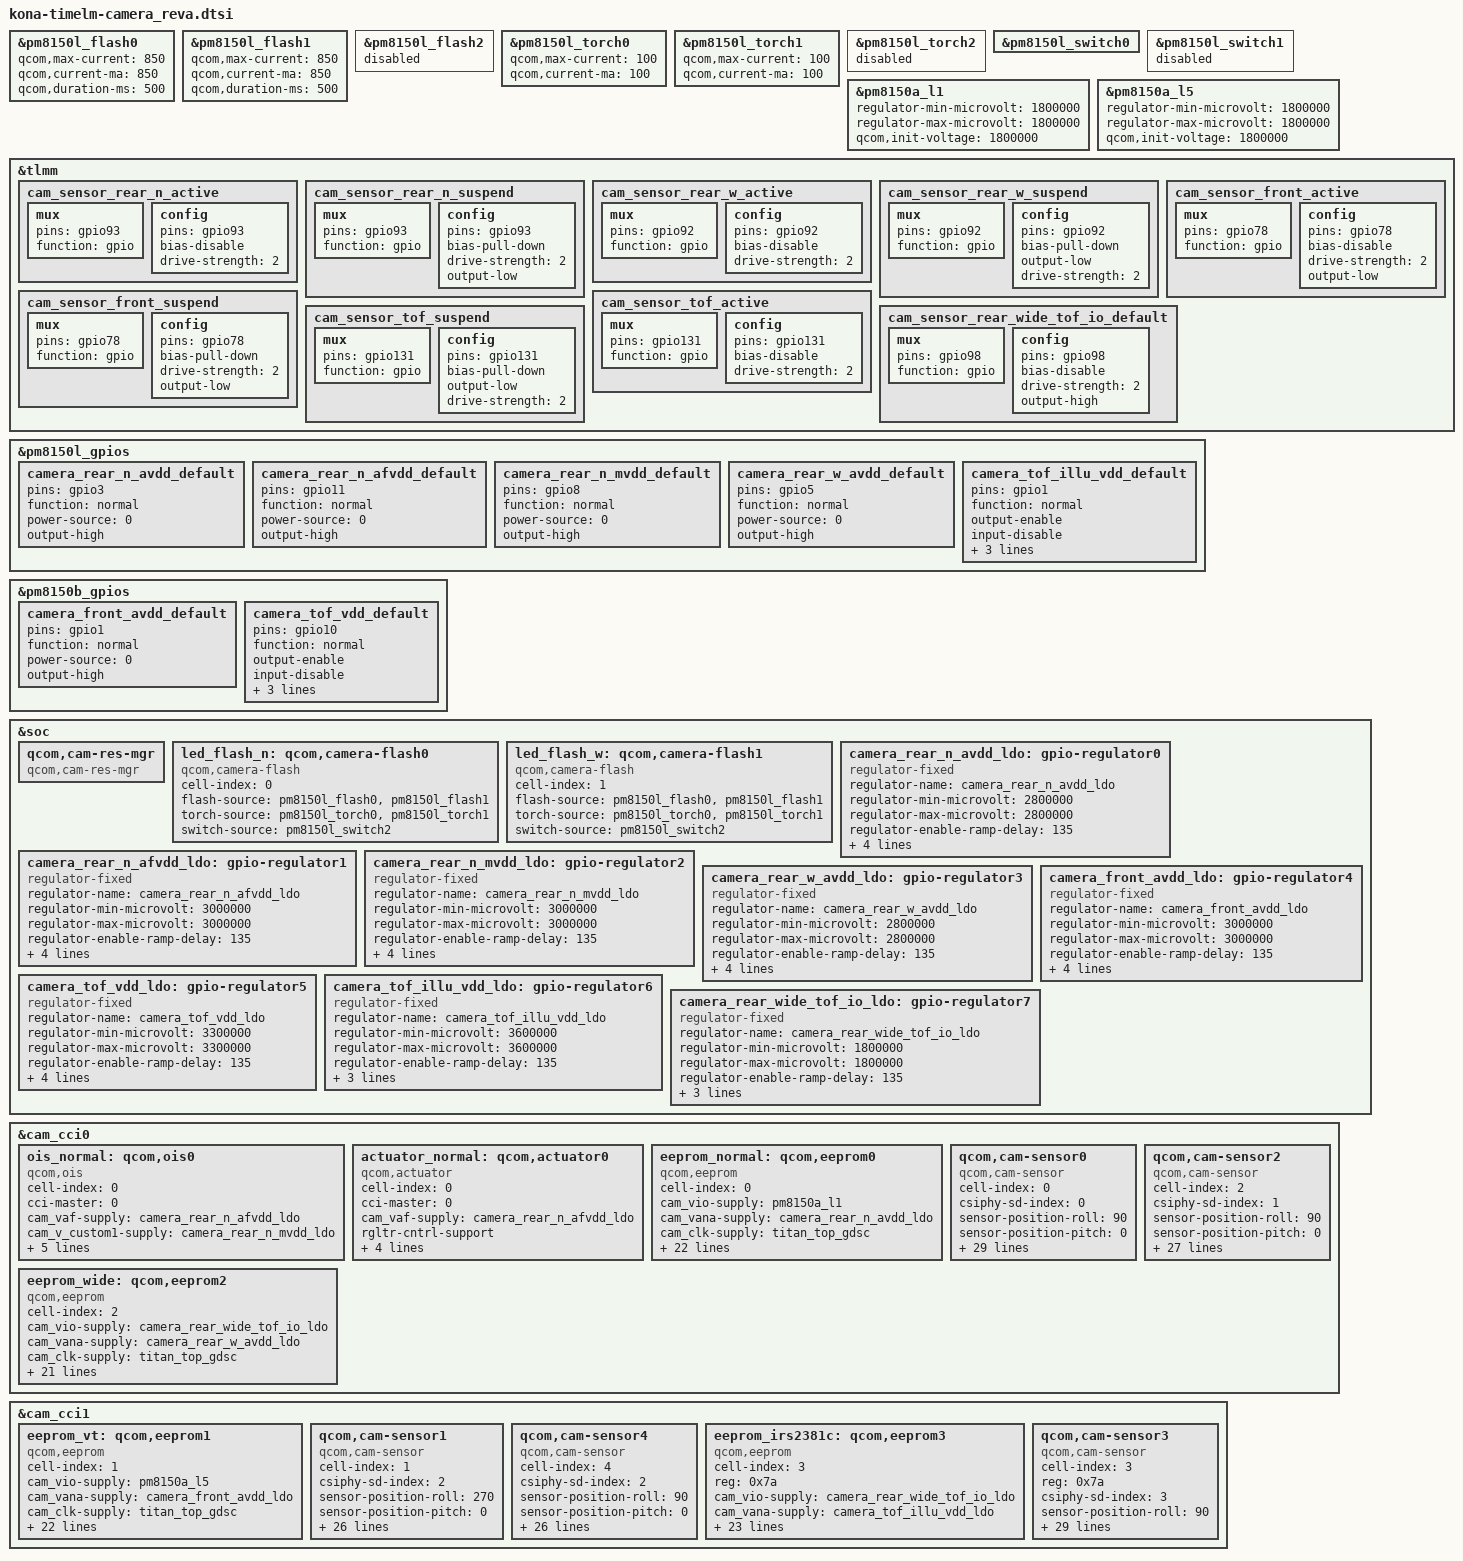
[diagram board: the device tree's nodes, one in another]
// SPDX-License-Identifier: GPL-2.0-only
/*
 * Copyright (c) 2018-2019, The Linux Foundation. All rights reserved.
 */

&pm8150l_flash0 {
	status = "ok";
	qcom,max-current = <850>;
	qcom,current-ma = <850>;
	qcom,duration-ms = <500>;
};

&pm8150l_flash1 {
	status = "ok";
	qcom,max-current = <850>;
	qcom,current-ma = <850>;
	qcom,duration-ms = <500>;
};

&pm8150l_flash2 {
	status = "disabled";
};

&pm8150l_torch0 {
	status = "ok";
	qcom,max-current = <100>;
	qcom,current-ma = <100>;
};

&pm8150l_torch1 {
	status = "ok";
	qcom,max-current = <100>;
	qcom,current-ma = <100>;
};

&pm8150l_torch2 {
	status = "disabled";
};

&pm8150l_switch0 {
	status = "ok";
};

&pm8150l_switch1 {
	status = "disbled";
};

&pm8150a_l1 {
	regulator-min-microvolt = <1800000>;
	regulator-max-microvolt = <1800000>;
	qcom,init-voltage = <1800000>;
};

&pm8150a_l5 {
	regulator-min-microvolt = <1800000>;
	regulator-max-microvolt = <1800000>;
	qcom,init-voltage = <1800000>;
};

&tlmm{
	cam_sensor_rear_n_active: cam_sensor_rear_n_active {
		mux {
			pins = "gpio93";
			function = "gpio";
		};

		config {
			pins = "gpio93";
			bias-disable;
			drive-strength = <2>;
		};
	};

	cam_sensor_rear_n_suspend: cam_sensor_rear_n_suspend {
		mux {
			pins = "gpio93";
			function = "gpio";
		};

		config {
			pins = "gpio93";
			bias-pull-down;
			drive-strength = <2>;
			output-low;
		};
	};

	cam_sensor_rear_w_active: cam_sensor_rear_w_active {
		mux {
			pins = "gpio92";
			function = "gpio";
		};

		config {
			pins = "gpio92";
			bias-disable;
			drive-strength = <2>;
		};
	};

	cam_sensor_rear_w_suspend: cam_sensor_rear_w_suspend {
		mux {
			pins = "gpio92";
			function = "gpio";
		};

		config {
			pins = "gpio92";
			bias-pull-down;
			output-low;
			drive-strength = <2>;
		};
	};

	cam_sensor_front_active: cam_sensor_front_active {
		mux {
			pins = "gpio78";
			function = "gpio";
		};

		config {
			pins = "gpio78";
			bias-disable;
			drive-strength = <2>;
			output-low;
		};
	};

	cam_sensor_front_suspend: cam_sensor_front_suspend {
		mux {
			pins = "gpio78";
			function = "gpio";
		};

		config {
			pins = "gpio78";
			bias-pull-down;
			drive-strength = <2>;
			output-low;
		};
	};

	cam_sensor_tof_active: cam_sensor_tof_active {
		mux {
			pins = "gpio131";
			function = "gpio";
		};

		config {
			pins = "gpio131";
			bias-disable;
			drive-strength = <2>;
		};
	};

	cam_sensor_tof_suspend: cam_sensor_tof_suspend {
		mux {
			pins = "gpio131";
			function = "gpio";
		};

		config {
			pins = "gpio131";
			bias-pull-down;
			output-low;
			drive-strength = <2>;
		};
	};

	cam_sensor_rear_wide_tof_io_default: cam_sensor_rear_wide_tof_io_default {
		mux {
			pins = "gpio98";
			function = "gpio";
		};

		config {
			pins = "gpio98";
			bias-disable;
			drive-strength = <2>;
			output-high;
		};
	};
};

&pm8150l_gpios {
	camera_rear_n_avdd_default: camera_rear_n_avdd_default {
		pins = "gpio3";
		function = "normal";
		power-source = <0>;
		output-high;
	};
	camera_rear_n_afvdd_default: camera_rear_n_afvdd_default {
		pins = "gpio11";
		function = "normal";
		power-source = <0>;
		output-high;
	};
	camera_rear_n_mvdd_default: camera_rear_n_mvdd_default {
		pins = "gpio8";
		function = "normal";
		power-source = <0>;
		output-high;
	};

	camera_rear_w_avdd_default: camera_rear_w_avdd_default {
		pins = "gpio5";
		function = "normal";
		power-source = <0>;
		output-high;
	};

	camera_tof_illu_vdd_default: camera_tof_illu_vdd_default {
		pins = "gpio1";
		function = "normal";
		output-enable;
		input-disable;
		bias-disable;
		drive-push-pull;
		power-source = <0>;
	};
};

&pm8150b_gpios {
	camera_front_avdd_default: camera_front_avdd_default {
		pins = "gpio1";
		function = "normal";
		power-source = <0>;
		output-high;
	};

/*
	cam_sensor_front_afvdd: cam_sensor_front_afvdd {
		pins = "gpio3";
		function = "normal";
		power-source = <0>;
		output-high;
	};
*/

	camera_tof_vdd_default: camera_tof_vdd_default {
		pins = "gpio10";
		function = "normal";
		output-enable;
		input-disable;
		bias-disable;
		drive-push-pull;
		power-source = <0>;
	};
};

&soc {
	qcom,cam-res-mgr {
		compatible = "qcom,cam-res-mgr";
		status = "ok";
	};

	led_flash_n: qcom,camera-flash0 {
		cell-index = <0>;
		compatible = "qcom,camera-flash";
		flash-source = <&pm8150l_flash0 &pm8150l_flash1>;
		torch-source = <&pm8150l_torch0 &pm8150l_torch1>;
		switch-source = <&pm8150l_switch2>;
		status = "ok";
	};

	led_flash_w: qcom,camera-flash1 {
		cell-index = <1>;
		compatible = "qcom,camera-flash";
		flash-source = <&pm8150l_flash0 &pm8150l_flash1>;
		torch-source = <&pm8150l_torch0 &pm8150l_torch1>;
		switch-source = <&pm8150l_switch2>;
		status = "ok";
	};

	camera_rear_n_avdd_ldo: gpio-regulator0 {
		compatible = "regulator-fixed";
		regulator-name = "camera_rear_n_avdd_ldo";
		regulator-min-microvolt = <2800000>;
		regulator-max-microvolt = <2800000>;
		regulator-enable-ramp-delay = <135>;
		enable-active-high;
		gpio = <&pm8150l_gpios 3 0>;
		pinctrl-names = "default";
		pinctrl-0 = <&camera_rear_n_avdd_default>;
		vin-supply = <&pm8150a_bob>;
	};

	camera_rear_n_afvdd_ldo: gpio-regulator1 {
		compatible = "regulator-fixed";
		regulator-name = "camera_rear_n_afvdd_ldo";
		regulator-min-microvolt = <3000000>;
		regulator-max-microvolt = <3000000>;
		regulator-enable-ramp-delay = <135>;
		enable-active-high;
		gpio = <&pm8150l_gpios 11 0>;
		pinctrl-names = "default";
		pinctrl-0 = <&camera_rear_n_afvdd_default>;
		vin-supply = <&pm8150a_bob>;
	};

	camera_rear_n_mvdd_ldo: gpio-regulator2 {
		compatible = "regulator-fixed";
		regulator-name = "camera_rear_n_mvdd_ldo";
		regulator-min-microvolt = <3000000>;
		regulator-max-microvolt = <3000000>;
		regulator-enable-ramp-delay = <135>;
		enable-active-high;
		gpio = <&pm8150l_gpios 8 0>;
		pinctrl-names = "default";
		pinctrl-0 = <&camera_rear_n_mvdd_default>;
		vin-supply = <&pm8150a_bob>;
	};
	camera_rear_w_avdd_ldo: gpio-regulator3{
		compatible = "regulator-fixed";
		regulator-name = "camera_rear_w_avdd_ldo";
		regulator-min-microvolt = <2800000>;
		regulator-max-microvolt = <2800000>;
		regulator-enable-ramp-delay = <135>;
		enable-active-high;
		gpio = <&pm8150l_gpios 5 0>;
		pinctrl-names = "default";
		pinctrl-0 = <&camera_rear_w_avdd_default>;
		vin-supply = <&pm8150a_bob>;
	};


	camera_front_avdd_ldo: gpio-regulator4 {
		compatible = "regulator-fixed";
		regulator-name = "camera_front_avdd_ldo";
		regulator-min-microvolt = <3000000>;
		regulator-max-microvolt = <3000000>;
		regulator-enable-ramp-delay = <135>;
		enable-active-high;
		gpio = <&pm8150b_gpios 1 0>;
		pinctrl-names = "default";
		pinctrl-0 = <&camera_front_avdd_default>;
		vin-supply = <&pm8150a_bob>;
	};

/*	camera_front_afvdd_ldo: gpio-regulator5 {
		compatible = "regulator-fixed";
		regulator-name = "camera_front_afvdd_ldo";
		regulator-min-microvolt = <2800000>;
		regulator-max-microvolt = <2800000>;
		regulator-enable-ramp-delay = <135>;
		enable-active-high;
		gpio = <&pm8150b_gpios 3 0>;
		pinctrl-names = "default";
		pinctrl-0 = <&cam_sensor_front_afvdd>;
		vin-supply = <&pm8150l_bob>;
	};*/
	camera_tof_vdd_ldo: gpio-regulator5 {
		compatible = "regulator-fixed";
		regulator-name = "camera_tof_vdd_ldo";
		regulator-min-microvolt = <3300000>;
		regulator-max-microvolt = <3300000>;
		regulator-enable-ramp-delay = <135>;
		enable-active-high;
		gpio = <&pm8150b_gpios 10 0>;
		pinctrl-names = "default";
		pinctrl-0 = <&camera_tof_vdd_default>;
		vin-supply = <&pm8150a_bob>;
	};

	camera_tof_illu_vdd_ldo: gpio-regulator6 {
		compatible = "regulator-fixed";
		regulator-name = "camera_tof_illu_vdd_ldo";
		regulator-min-microvolt = <3600000>;
		regulator-max-microvolt = <3600000>;
		regulator-enable-ramp-delay = <135>;
		enable-active-high;
		gpio = <&pm8150l_gpios 1 0>;
		pinctrl-names = "default";
		pinctrl-0 = <&camera_tof_illu_vdd_default>;
	};

	camera_rear_wide_tof_io_ldo: gpio-regulator7 {
		compatible = "regulator-fixed";
		regulator-name = "camera_rear_wide_tof_io_ldo";
		regulator-min-microvolt = <1800000>;
		regulator-max-microvolt = <1800000>;
		regulator-enable-ramp-delay = <135>;
		enable-active-high;
		gpio = <&tlmm 98 0>;
		pinctrl-names = "default";
		pinctrl-0 = <&cam_sensor_rear_wide_tof_io_default>;
	};
};

&cam_cci0 {
	ois_normal: qcom,ois0 {
		cell-index = <0>;
		compatible = "qcom,ois";
		cci-master = <0>;
		cam_vaf-supply = <&camera_rear_n_afvdd_ldo>;
		cam_v_custom1-supply = <&camera_rear_n_mvdd_ldo>;
		regulator-names = "cam_vaf","cam_v_custom1";
		rgltr-cntrl-support;
		rgltr-min-voltage = <3000000 3000000>;
		rgltr-max-voltage = <3000000 3000000>;
		rgltr-load-current = <0 0>;
		status = "ok";
	};

	actuator_normal: qcom,actuator0 {
		cell-index = <0>;
		compatible = "qcom,actuator";
		cci-master = <0>;
		cam_vaf-supply = <&camera_rear_n_afvdd_ldo>;
		rgltr-cntrl-support;
		regulator-names = "cam_vaf";
		rgltr-min-voltage = <3000000>;
		rgltr-max-voltage = <3000000>;
		rgltr-load-current = <0>;
	};

	eeprom_normal: qcom,eeprom0 {
		cell-index = <0>;
		compatible = "qcom,eeprom";
		cam_vio-supply = <&pm8150a_l1>;
		cam_vana-supply = <&camera_rear_n_avdd_ldo>;
		//cam_vdig-supply = <&camera_rear_n_dvdd_ldo>;
		cam_clk-supply = <&titan_top_gdsc>;
		regulator-names = "cam_vio", "cam_vana", "cam_clk";
		rgltr-cntrl-support;
		rgltr-min-voltage = <1800000 2800000 0>;
		rgltr-max-voltage = <1800000 2800000 0>;
		rgltr-load-current = <150000 150000 0>;
		gpio-no-mux = <0>;
		pinctrl-names = "cam_default", "cam_suspend";
		pinctrl-0 = <&cam_sensor_mclk0_active
				&cam_sensor_rear_n_active>;
		pinctrl-1 = <&cam_sensor_mclk0_suspend
				&cam_sensor_rear_n_suspend>;
		gpios = <&tlmm 94 0>,
			<&tlmm 93 0>;
		gpio-reset = <1>;
		gpio-req-tbl-num = <0 1>;
		gpio-req-tbl-flags = <1 0>;
		gpio-req-tbl-label = "CAMIF_MCLK0",
					"CAM_RESET0";
		sensor-position = <0>;
		sensor-mode = <0>;
		cci-device = <0>;
		cci-master = <0>;
		status = "ok";
		clocks = <&clock_camcc CAM_CC_MCLK0_CLK>;
		clock-names = "cam_clk";
		clock-cntl-level = "turbo";
		clock-rates = <19200000>;
	};

	qcom,cam-sensor0 {
		cell-index = <0>;
		compatible = "qcom,cam-sensor";
		csiphy-sd-index = <0>;
		sensor-position-roll = <90>;
		sensor-position-pitch = <0>;
		sensor-position-yaw = <180>;
		ois-src = <&ois_normal>;
		actuator-src = <&actuator_normal>;
		eeprom-src = <&eeprom_normal>;
		led-flash-src = <&led_flash_n>;
		cam_vio-supply = <&pm8150a_l1>;
		cam_vana-supply = <&camera_rear_n_avdd_ldo>;
		//cam_vdig-supply = <&camera_rear_n_dvdd_ldo>;
		cam_clk-supply = <&titan_top_gdsc>;
		regulator-names = "cam_vio", "cam_vana", "cam_clk";
		rgltr-cntrl-support;
		rgltr-min-voltage = <1800000 2800000 0>;
		rgltr-max-voltage = <1800000 2800000 0>;
		rgltr-load-current = <150000 150000 0>;
		gpio-no-mux = <0>;
		pinctrl-names = "cam_default", "cam_suspend";
		pinctrl-0 = <&cam_sensor_mclk0_active
				 &cam_sensor_rear_n_active>;
		pinctrl-1 = <&cam_sensor_mclk0_suspend
				 &cam_sensor_rear_n_suspend>;
		gpios = <&tlmm 94 0>,
			<&tlmm 93 0>;
		gpio-reset = <1>;
		gpio-req-tbl-num = <0 1>;
		gpio-req-tbl-flags = <1 0>;
		gpio-req-tbl-label = "CAMIF_MCLK0",
					"CAM_RESET0";
		sensor-mode = <0>;
		cci-device = <0>;
		cci-master = <0>;
		status = "ok";
		clocks = <&clock_camcc CAM_CC_MCLK0_CLK>;
		clock-names = "cam_clk";
		clock-cntl-level = "turbo";
		clock-rates = <19200000>;
	};

	eeprom_wide: qcom,eeprom2 {
		cell-index = <2>;
		compatible = "qcom,eeprom";
		cam_vio-supply = <&camera_rear_wide_tof_io_ldo>;
		cam_vana-supply = <&camera_rear_w_avdd_ldo>;
		//cam_vdig-supply = <&camera_rear_w_dvdd_ldo>;
		cam_clk-supply = <&titan_top_gdsc>;
		regulator-names = "cam_vio", "cam_vana", "cam_clk";
		rgltr-cntrl-support;
		rgltr-min-voltage = <1800000 2800000 0>;
		rgltr-max-voltage = <1800000 2800000 0>;
		rgltr-load-current = <150000 150000 0>;
		gpio-no-mux = <0>;
		pinctrl-names = "cam_default", "cam_suspend";
		pinctrl-0 = <&cam_sensor_mclk1_active
				&cam_sensor_rear_w_active>;
		pinctrl-1 = <&cam_sensor_mclk1_suspend
				&cam_sensor_rear_w_suspend>;
		gpios = <&tlmm 95 0>,
			<&tlmm 92 0>;
		gpio-reset = <1>;
		gpio-req-tbl-num = <0 1>;
		gpio-req-tbl-flags = <1 0>;
		gpio-req-tbl-label = "CAMIF_MCLK1",
					"CAM_RESET1";
		sensor-mode = <0>;
		cci-device = <0>;
		cci-master = <1>;
		status = "ok";
		clocks = <&clock_camcc CAM_CC_MCLK1_CLK>;
		clock-names = "cam_clk";
		clock-cntl-level = "turbo";
		clock-rates = <19200000>;
	};

	qcom,cam-sensor2 {
		cell-index = <2>;
		compatible = "qcom,cam-sensor";
		csiphy-sd-index = <1>;
		sensor-position-roll = <90>;
		sensor-position-pitch = <0>;
		sensor-position-yaw = <180>;
		led-flash-src = <&led_flash_w>;
		eeprom-src = <&eeprom_wide>;
		cam_vio-supply = <&camera_rear_wide_tof_io_ldo>;
		cam_vana-supply = <&camera_rear_w_avdd_ldo>;
		//cam_vdig-supply = <&camera_rear_w_dvdd_ldo>;
		cam_clk-supply = <&titan_top_gdsc>;
		regulator-names = "cam_vio", "cam_vana", "cam_clk";
		rgltr-cntrl-support;
		rgltr-min-voltage = <1800000 2800000 0>;
		rgltr-max-voltage = <1800000 2800000 0>;
		rgltr-load-current = <150000 150000 0>;
		gpio-no-mux = <0>;
		pinctrl-names = "cam_default", "cam_suspend";
		pinctrl-0 = <&cam_sensor_mclk1_active
				&cam_sensor_rear_w_active>;
		pinctrl-1 = <&cam_sensor_mclk1_suspend
				&cam_sensor_rear_w_suspend>;
		gpios = <&tlmm 95 0>,
			<&tlmm 92 0>;
		gpio-reset = <1>;
		gpio-req-tbl-num = <0 1>;
		gpio-req-tbl-flags = <1 0>;
		gpio-req-tbl-label = "CAMIF_MCLK1",
					"CAM_RESET1";
		sensor-mode = <0>;
		cci-device = <0>;
		cci-master = <1>;
		status = "ok";
		clocks = <&clock_camcc CAM_CC_MCLK1_CLK>;
		clock-names = "cam_clk";
		clock-cntl-level = "turbo";
		clock-rates = <19200000>;
	};
};

&cam_cci1 {
/*	actuator_vt: qcom,actuator1 {
		cell-index = <1>;
		compatible = "qcom,actuator";
		cam_vaf-supply = <&camera_front_afvdd_ldo>;
		rgltr-cntrl-support;
		regulator-names = "cam_vaf";
		rgltr-min-voltage = <2800000>;
		rgltr-max-voltage = <2800000>;
		rgltr-load-current = <0>;
		status = "ok";
		cci-device = <1>;
		cci-master = <0>;
	};
*/
	eeprom_vt: qcom,eeprom1 {
		cell-index = <1>;
		compatible = "qcom,eeprom";
		cam_vio-supply = <&pm8150a_l5>;
		cam_vana-supply = <&camera_front_avdd_ldo>;
		//cam_vdig-supply = <&camera_front_dvdd_ldo>;
		cam_clk-supply = <&titan_top_gdsc>;
		regulator-names = "cam_vio", "cam_vana", "cam_clk";
		rgltr-cntrl-support;
		rgltr-min-voltage = <1800000 3000000 0>;
		rgltr-max-voltage = <1800000 3000000 0>;
		rgltr-load-current = <150000 150000 0>;
		gpio-no-mux = <0>;
		pinctrl-names = "cam_default", "cam_suspend";
		pinctrl-0 = <&cam_sensor_mclk2_active
				 &cam_sensor_front_active>;
		pinctrl-1 = <&cam_sensor_mclk2_suspend
				 &cam_sensor_front_suspend>;
		gpios = <&tlmm 96 0>,
			<&tlmm 78 0>;
		gpio-reset = <1>;
		gpio-req-tbl-num = <0 1>;
		gpio-req-tbl-flags = <1 0>;
		gpio-req-tbl-label = "VT_MCLK",
					"VT_RESET";
		sensor-position = <0>;
		sensor-mode = <0>;
		cci-device = <1>;
		cci-master = <0>;
		status = "ok";
		clocks = <&clock_camcc CAM_CC_MCLK2_CLK>;
		clock-names = "cam_clk";
		clock-cntl-level = "turbo";
		clock-rates = <19200000>;
	};

	qcom,cam-sensor1 {
		cell-index = <1>;
		compatible = "qcom,cam-sensor";
		csiphy-sd-index = <2>;
		sensor-position-roll = <270>;
		sensor-position-pitch = <0>;
		sensor-position-yaw = <0>;
		//actuator-src = <&actuator_vt>;
		eeprom-src = <&eeprom_vt>;
		cam_vio-supply = <&pm8150a_l5>;
		cam_vana-supply = <&camera_front_avdd_ldo>;
		//cam_vdig-supply = <&camera_front_dvdd_ldo>;
		cam_clk-supply = <&titan_top_gdsc>;
		regulator-names = "cam_vio", "cam_vana", "cam_clk";
		rgltr-cntrl-support;
		rgltr-min-voltage = <1800000 3000000 0>;
		rgltr-max-voltage = <1800000 3000000 0>;
		rgltr-load-current = <150000 150000 0>;
		gpio-no-mux = <0>;
		pinctrl-names = "cam_default", "cam_suspend";
		pinctrl-0 = <&cam_sensor_mclk2_active
				 &cam_sensor_front_active>;
		pinctrl-1 = <&cam_sensor_mclk2_suspend
				 &cam_sensor_front_suspend>;
		gpios = <&tlmm 96 0>,
			<&tlmm 78 0>;
		gpio-reset = <1>;
		gpio-req-tbl-num = <0 1>;
		gpio-req-tbl-flags = <1 0>;
		gpio-req-tbl-label = "VT_MCLK",
					"VT_RESET";
		sensor-mode = <0>;
		cci-device = <1>;
		cci-master = <0>;
		status = "ok";
		clocks = <&clock_camcc CAM_CC_MCLK2_CLK>;
		clock-names = "cam_clk";
		clock-cntl-level = "turbo";
		clock-rates = <19200000>;
	};

	qcom,cam-sensor4 {
		cell-index = <4>;
		compatible = "qcom,cam-sensor";
		csiphy-sd-index = <2>;
		sensor-position-roll = <90>;
		sensor-position-pitch = <0>;
		sensor-position-yaw = <0>;
		//actuator-src = <&actuator_vt>;
		eeprom-src = <&eeprom_vt>;
		cam_vio-supply = <&pm8150a_l5>;
		cam_vana-supply = <&camera_front_avdd_ldo>;
		//cam_vdig-supply = <&camera_front_dvdd_ldo>;
		cam_clk-supply = <&titan_top_gdsc>;
		regulator-names = "cam_vio", "cam_vana", "cam_clk";
		rgltr-cntrl-support;
		rgltr-min-voltage = <1800000 3000000 0>;
		rgltr-max-voltage = <1800000 3000000 0>;
		rgltr-load-current = <150000 150000 0>;
		gpio-no-mux = <0>;
		pinctrl-names = "cam_default", "cam_suspend";
		pinctrl-0 = <&cam_sensor_mclk2_active
				 &cam_sensor_front_active>;
		pinctrl-1 = <&cam_sensor_mclk2_suspend
				 &cam_sensor_front_suspend>;
		gpios = <&tlmm 96 0>,
			<&tlmm 78 0>;
		gpio-reset = <1>;
		gpio-req-tbl-num = <0 1>;
		gpio-req-tbl-flags = <1 0>;
		gpio-req-tbl-label = "VT_MCLK",
					"VT_RESET";
		sensor-mode = <0>;
		cci-device = <1>;
		cci-master = <0>;
		status = "ok";
		clocks = <&clock_camcc CAM_CC_MCLK2_CLK>;
		clock-names = "cam_clk";
		clock-cntl-level = "turbo";
		clock-rates = <19200000>;
	};

	eeprom_irs2381c: qcom,eeprom3 {
		cell-index = <3>;
		reg = <0x7a>;
		compatible = "qcom,eeprom";
		cam_vio-supply = <&camera_rear_wide_tof_io_ldo>;
		cam_vana-supply = <&camera_tof_illu_vdd_ldo>;
		cam_vdig-supply = <&camera_tof_vdd_ldo>;
		cam_clk-supply = <&titan_top_gdsc>;
		regulator-names = "cam_vio", "cam_vana", "cam_vdig",
			"cam_clk";
		rgltr-cntrl-support;
		rgltr-min-voltage = <1800000 3600000 3300000 0>;
		rgltr-max-voltage = <1800000 3600000 3300000 0>;
		rgltr-load-current = <150000 580000 110000 0>;
		gpio-no-mux = <0>;
		pinctrl-names = "cam_default", "cam_suspend";
		pinctrl-0 = <&cam_sensor_mclk3_active
				 &cam_sensor_tof_active>;
		pinctrl-1 = <&cam_sensor_mclk3_suspend
				 &cam_sensor_tof_suspend>;
		gpios = <&tlmm 97 0>,
			<&tlmm 109 0>;
		gpio-reset = <1>;
		gpio-req-tbl-num = <0 1>;
		gpio-req-tbl-flags = <1 0>;
		gpio-req-tbl-label = "CAMIF_MCLK3",
					"CAM_RESET3";
		cci-device = <1>;
		cci-master = <1>;
		status = "ok";
		clocks = <&clock_camcc CAM_CC_MCLK3_CLK>;
		clock-names = "cam_clk";
		clock-cntl-level = "turbo";
		clock-rates = <19200000>;
	};

	qcom,cam-sensor3 {
		cell-index = <3>;
		compatible = "qcom,cam-sensor";
		reg = <0x7a>;
		csiphy-sd-index = <3>;
		sensor-position-roll = <90>;
		sensor-position-pitch = <0>;
		sensor-position-yaw = <180>;
		eeprom-src = <&eeprom_irs2381c>;
		cam_vio-supply = <&camera_rear_wide_tof_io_ldo>;
		cam_vana-supply = <&camera_tof_illu_vdd_ldo>;
		cam_vdig-supply = <&camera_tof_vdd_ldo>;
		cam_clk-supply = <&titan_top_gdsc>;
		regulator-names = "cam_vio", "cam_vana", "cam_vdig",
			"cam_clk";
		rgltr-cntrl-support;
		rgltr-min-voltage = <1800000 3600000 3300000 0>;
		rgltr-max-voltage = <1800000 3600000 3300000 0>;
		rgltr-load-current = <150000 580000 110000 0>;
		gpio-no-mux = <0>;
		pinctrl-names = "cam_default", "cam_suspend";
		pinctrl-0 = <&cam_sensor_mclk3_active
				 &cam_sensor_tof_active>;
		pinctrl-1 = <&cam_sensor_mclk3_suspend
				 &cam_sensor_tof_suspend>;
		gpios = <&tlmm 97 0>,
			<&tlmm 109 0>;
		gpio-reset = <1>;
		gpio-req-tbl-num = <0 1>;
		gpio-req-tbl-flags = <1 0>;
		gpio-req-tbl-label = "CAMIF_MCLK3",
					"CAM_RESET3";
		sensor-mode = <0>;
		cci-device = <1>;
		cci-master = <1>;
		status = "ok";
		clocks = <&clock_camcc CAM_CC_MCLK3_CLK>;
		clock-names = "cam_clk";
		clock-cntl-level = "turbo";
		clock-rates = <19200000>;
	};
};
